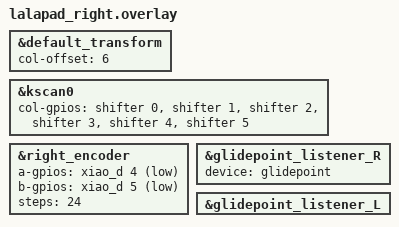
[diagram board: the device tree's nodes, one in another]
#include "lalapad.dtsi"

&default_transform {
    col-offset = <6>;
};

&kscan0 {
    col-gpios
        = <&shifter 0 GPIO_ACTIVE_HIGH>
        , <&shifter 1 GPIO_ACTIVE_HIGH>
        , <&shifter 2 GPIO_ACTIVE_HIGH>
        , <&shifter 3 GPIO_ACTIVE_HIGH>
        , <&shifter 4 GPIO_ACTIVE_HIGH>
        , <&shifter 5 GPIO_ACTIVE_HIGH>
        ;
};

&right_encoder {
    a-gpios = <&xiao_d 4 (GPIO_ACTIVE_LOW | GPIO_PULL_UP)>;
    b-gpios = <&xiao_d 5 (GPIO_ACTIVE_LOW | GPIO_PULL_UP)>;
    steps = <24>;
    status = "okay";
};

&glidepoint_listener_R {
    status = "okay";
    device = <&glidepoint>;
};
&glidepoint_listener_L {
    status = "okay";
};
